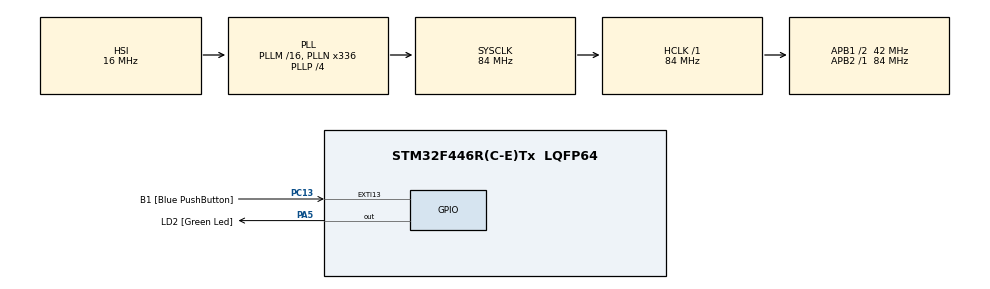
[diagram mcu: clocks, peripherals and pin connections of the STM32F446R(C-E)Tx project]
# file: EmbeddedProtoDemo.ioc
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Mcu.Family=STM32F4
Mcu.Name=STM32F446R(C-E)Tx
Mcu.Package=LQFP64
NVIC.PriorityGroup=NVIC_PRIORITYGROUP_0
PA13.GPIO_Label=TMS
PA13.Signal=SYS_JTMS-SWDIO
PA14.GPIO_Label=TCK
PA14.Signal=SYS_JTCK-SWCLK
PA2.GPIO_Label=USART_TX
PA2.Signal=USART2_TX
PA3.GPIO_Label=USART_RX
PA3.Signal=USART2_RX
PA5.GPIO_Label=LD2 [Green Led]
PA5.Signal=GPIO_Output
PB3.GPIO_Label=SWO
PB3.Signal=SYS_JTDO-SWO
PC13.GPIO_Label=B1 [Blue PushButton]
PC13.GPIO_ModeDefaultEXTI=GPIO_MODE_IT_FALLING
PC13.Signal=GPXTI13
PC14-OSC32_IN.Signal=RCC_OSC32_IN
PC15-OSC32_OUT.Signal=RCC_OSC32_OUT
PH0-OSC_IN.Signal=RCC_OSC_IN
PH1-OSC_OUT.Signal=RCC_OSC_OUT
ProjectManager.HeapSize=0x200
ProjectManager.StackSize=0x400
ProjectManager.TargetToolchain=STM32CubeIDE
RCC.AHBFreq_Value=84000000
RCC.APB1CLKDivider=RCC_HCLK_DIV2
RCC.APB1Freq_Value=42000000
RCC.APB1TimFreq_Value=84000000
RCC.APB2Freq_Value=84000000
RCC.APB2TimFreq_Value=84000000
RCC.CortexFreq_Value=84000000
RCC.FLatency-AdvancedSettings=FLASH_LATENCY_2
RCC.HCLKFreq_Value=84000000
RCC.HSE_VALUE=8000000
RCC.HSI_VALUE=16000000
RCC.LSE_VALUE=32768
RCC.PLLN=336
RCC.PLLP=RCC_PLLP_DIV4
RCC.SYSCLKFreq_VALUE=84000000
RCC.SYSCLKSource=RCC_SYSCLKSOURCE_PLLCLK
RCC.USBFreq_Value=168000000
RCC.VCOOutputFreq_Value=336000000
board=NUCLEO-F446RE

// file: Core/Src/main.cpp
/* USER CODE BEGIN Header */
/**
  ******************************************************************************
  * @file           : main.c
  * @brief          : Main program body
  ******************************************************************************
  * @attention
  *
  * <h2><center>&copy; Copyright (c) 2020 STMicroelectronics.
  * All rights reserved.</center></h2>
  *
  * This software component is licensed by ST under BSD 3-Clause license,
  * the "License"; You may not use this file except in compliance with the
  * License. You may obtain a copy of the License at:
  *                        opensource.org/licenses/BSD-3-Clause
  *
  ******************************************************************************
  */
/* USER CODE END Header */

#include "main.h"

/* USER CODE BEGIN Includes */
#include <reply.h>
#include <request.h>
#include <DemoWriteBuffer.h>
#include <DemoReadBuffer.h>

/* USER CODE END Includes */

/* USER CODE BEGIN PV */
// Construction of the messages.
demo::reply reply_msg;
demo::request request_msg;

// Construction of the write and read buffer objects.
demo::WriteBuffer<50> send_buffer;
demo::ReadBuffer read_buffer;

/* USER CODE END PV */

void SystemClock_Config(void);
static void MX_GPIO_Init(void);

int main(void)
{
  /* USER CODE BEGIN 1 */
  uint32_t request_counter = 0;
  /* USER CODE END 1 */

  /* MCU Configuration--------------------------------------------------------*/

  /* Reset of all peripherals, Initializes the Flash interface and the Systick. */
  HAL_Init();

  /* Configure the system clock */
  SystemClock_Config();

  /* Initialize all configured peripherals */
  MX_GPIO_Init();

  /* Infinite loop */
  while (1)
  {
    // Increment the request counter each iteration and alternate between request A and B.
    request_msg.set_msgId(++request_counter);
    request_msg.set_selection((request_counter & 0x01) ? demo::types::A
                                                       : demo::types::B);

    if(request_msg.serialize(send_buffer))
    {
      // Serialization is successful. We can now use the buffer to send the data via a peripheral.
    }
    else
    {
      // Serialization failed for some reason.
    }

    // For demo purposes manually set the demo data.
    if(request_counter & 0x01)
    {
      // Data for A
      constexpr uint32_t RESPONS_SIZE_A = 10;
      uint8_t demo_response_A[RESPONS_SIZE_A] = {0x08, 0x01, 0x12, 0x06, 0x08, 0x0A, 0x10, 0x14,
    		  0x18, 0x1E};

      read_buffer.set_demo_data(demo_response_A, RESPONS_SIZE_A);
    }
    else
    {
      // Data for B
      constexpr uint32_t RESPONS_SIZE_B = 31;
      uint8_t demo_response_B[RESPONS_SIZE_B] = {0x08, 0x02, 0x1A, 0x1B, 0x09, 0x00, 0x00, 0x00,
    		  0x00, 0x00, 0x00, 0x59, 0x40, 0x11, 0x00, 0x00, 0x00, 0x00, 0x00, 0x00, 0x69, 0x40,
			  0x19, 0x00, 0x00, 0x00, 0x00, 0x00, 0xC0, 0x72, 0x40};

      read_buffer.set_demo_data(demo_response_B, RESPONS_SIZE_B);
    }

    // Obtain from the buffer the reply message.
    if(reply_msg.deserialize(read_buffer))
    {
      // Now we can use it.
      switch(reply_msg.get_which_type())
      {
        case demo::reply::id::A:
        {
          // Do something with the data.
          uint32_t ans_a = reply_msg.a().x() + reply_msg.a().y() + reply_msg.a().z();
          break;
        }

        case demo::reply::id::B:
        {
          // Do something with the data.
          uint32_t ans_b = reply_msg.b().u() * reply_msg.b().v() * reply_msg.b().w();
          break;
        }

        default:
          break;
      }
    }

  }
}

void SystemClock_Config(void)
{
  RCC_OscInitTypeDef RCC_OscInitStruct = {0};
  RCC_ClkInitTypeDef RCC_ClkInitStruct = {0};

  /** Configure the main internal regulator output voltage
  */
  __HAL_RCC_PWR_CLK_ENABLE();
  __HAL_PWR_VOLTAGESCALING_CONFIG(PWR_REGULATOR_VOLTAGE_SCALE3);
  /** Initializes the CPU, AHB and APB busses clocks
  */
  RCC_OscInitStruct.OscillatorType = RCC_OSCILLATORTYPE_HSI;
  RCC_OscInitStruct.HSIState = RCC_HSI_ON;
  RCC_OscInitStruct.HSICalibrationValue = RCC_HSICALIBRATION_DEFAULT;
  RCC_OscInitStruct.PLL.PLLState = RCC_PLL_ON;
  RCC_OscInitStruct.PLL.PLLSource = RCC_PLLSOURCE_HSI;
  RCC_OscInitStruct.PLL.PLLM = 16;
  RCC_OscInitStruct.PLL.PLLN = 336;
  RCC_OscInitStruct.PLL.PLLP = RCC_PLLP_DIV4;
  RCC_OscInitStruct.PLL.PLLQ = 2;
  RCC_OscInitStruct.PLL.PLLR = 2;
  if (HAL_RCC_OscConfig(&RCC_OscInitStruct) != HAL_OK)
  {
    Error_Handler();
  }
  /** Initializes the CPU, AHB and APB busses clocks
  */
  RCC_ClkInitStruct.ClockType = RCC_CLOCKTYPE_HCLK|RCC_CLOCKTYPE_SYSCLK
                              |RCC_CLOCKTYPE_PCLK1|RCC_CLOCKTYPE_PCLK2;
  RCC_ClkInitStruct.SYSCLKSource = RCC_SYSCLKSOURCE_PLLCLK;
  RCC_ClkInitStruct.AHBCLKDivider = RCC_SYSCLK_DIV1;
  RCC_ClkInitStruct.APB1CLKDivider = RCC_HCLK_DIV2;
  RCC_ClkInitStruct.APB2CLKDivider = RCC_HCLK_DIV1;

  if (HAL_RCC_ClockConfig(&RCC_ClkInitStruct, FLASH_LATENCY_2) != HAL_OK)
  {
    Error_Handler();
  }
}

static void MX_GPIO_Init(void)
{
  GPIO_InitTypeDef GPIO_InitStruct = {0};

  /* GPIO Ports Clock Enable */
  __HAL_RCC_GPIOC_CLK_ENABLE();
  __HAL_RCC_GPIOH_CLK_ENABLE();
  __HAL_RCC_GPIOA_CLK_ENABLE();
  __HAL_RCC_GPIOB_CLK_ENABLE();

  /*Configure GPIO pin Output Level */
  HAL_GPIO_WritePin(LD2_GPIO_Port, LD2_Pin, GPIO_PIN_RESET);

  /*Configure GPIO pin : B1_Pin */
  GPIO_InitStruct.Pin = B1_Pin;
  GPIO_InitStruct.Mode = GPIO_MODE_IT_FALLING;
  GPIO_InitStruct.Pull = GPIO_NOPULL;
  HAL_GPIO_Init(B1_GPIO_Port, &GPIO_InitStruct);

  /*Configure GPIO pins : USART_TX_Pin USART_RX_Pin */
  GPIO_InitStruct.Pin = USART_TX_Pin|USART_RX_Pin;
  GPIO_InitStruct.Mode = GPIO_MODE_AF_PP;
  GPIO_InitStruct.Pull = GPIO_NOPULL;
  GPIO_InitStruct.Speed = GPIO_SPEED_FREQ_VERY_HIGH;
  GPIO_InitStruct.Alternate = GPIO_AF7_USART2;
  HAL_GPIO_Init(GPIOA, &GPIO_InitStruct);

  /*Configure GPIO pin : LD2_Pin */
  GPIO_InitStruct.Pin = LD2_Pin;
  GPIO_InitStruct.Mode = GPIO_MODE_OUTPUT_PP;
  GPIO_InitStruct.Pull = GPIO_NOPULL;
  GPIO_InitStruct.Speed = GPIO_SPEED_FREQ_LOW;
  HAL_GPIO_Init(LD2_GPIO_Port, &GPIO_InitStruct);

}

void Error_Handler(void)
{
}

/************************ (C) COPYRIGHT STMicroelectronics *****END OF FILE****/
